AUTOSAR XML (schema 4-3-0)
standard types defined: uint16, uint32, boolean, uint8
package /DataTypes/ApplicationDataTypes
  app type uint16: category=VALUE, sw-calibration-access=READ-WRITE
  application record data type Position: category=STRUCTURE, sw-calibration-access=READ-WRITE
    application record element q: type=uint16
    application record element w: type=uint16
  app type uint32: category=VALUE, sw-calibration-access=READ-WRITE
  app type boolean: category=VALUE, sw-calibration-access=READ-WRITE
  application record data type VehicleInfo: category=STRUCTURE, sw-calibration-access=READ-WRITE
    application record element e: type=Position
    application record element r: type=uint32
    application record element t: type=boolean
  app type uint8: category=VALUE, sw-calibration-access=READ-WRITE
  application array data type uint8_array_10: category=ARRAY, sw-calibration-access=READ-WRITE
    element uint8_array_10: category=VALUE, type=uint8, array-size-semantics=FIXED-SIZE, max-number-of-elements=10
package /DataTypes/ImplementationDataTypes
  impl type Position: category=STRUCTURE
    element q: implementation-data-type=uint16
    element w: implementation-data-type=uint16
  impl type VehicleInfo: category=STRUCTURE
    element e: implementation-data-type=Position
    element r: implementation-data-type=uint32
    element t: implementation-data-type=boolean
  impl type uint8_array_10: category=TYPE_REFERENCE
    element Element: array-size=10, implementation-data-type=uint8
  5 x sender receiver interface:
    SpeedInput
      data SpeedInput: type=uint16
    ControlCmd
      data ControlCmd: type=boolean
    VehiclePos
      data VehiclePos: type=Position
    VehicleData
      data VehicleData: type=VehicleInfo
    SensorBuffer
      data SensorBuffer: type=uint8_array_10
package /Components
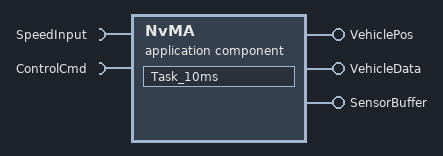
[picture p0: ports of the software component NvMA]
  application sw component type NvMA
    require port SpeedInput: nonqueued-receiver-com-spec=data-element=SpeedInput
    require port ControlCmd: nonqueued-receiver-com-spec=data-element=ControlCmd
    provide port VehiclePos: nonqueued-sender-com-spec=data-element=VehiclePos
    provide port VehicleData: nonqueued-sender-com-spec=data-element=VehicleData
    provide port SensorBuffer: nonqueued-sender-com-spec=data-element=SensorBuffer
    behavior NvMA_InternalBehavior: task-event={runnable-entity=Task_10ms, task-name=Task_10ms}
      runnable Task_10ms
        data-receive-point-by-arguments:
          access IN_SpeedInput_SpeedInput: accessed-variable=SpeedInput.SpeedInput
        data-receive-point-by-arguments:
          access IN_ControlCmd_ControlCmd: accessed-variable=ControlCmd.ControlCmd
        data-send-point-by-arguments:
          access OUT_VehicleData_VehicleData: accessed-variable=VehicleData.VehicleData
        data-send-point-by-arguments:
          access OUT_SensorBuffer_SensorBuffer: accessed-variable=SensorBuffer.SensorBuffer
